# A31L22x register map
Vendor: VENDOR ABOV Semiconductor Co., Ltd.; Series: A31L22x; File version: 1.0
CPU: CM0+ r0p1, little endian, no MPU, no FPU, VTOR, 2 interrupt priority bits
Registers are 32-bit, read-write, reset 0x0 unless marked. A register's access mark holds for its fields unless they carry their own. Offsets are from the block's base; [hi:lo] are bit positions.

## TIMER5n — Timer/Counter 5n
Base 0x55000000
Same registers: TIMER50 0x40002B00
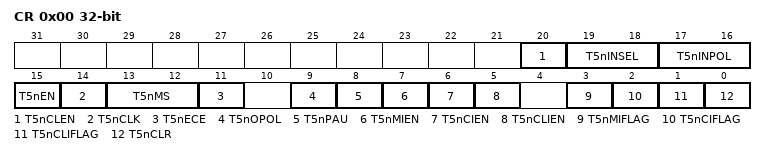
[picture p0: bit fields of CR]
0x00 CR — TIMER5n Control Register
  [20] T5nCLEN — TIMER5n Counter Clear Input Enable
    0=Disable counter clear input; 1=Enable counter clear input at a valid edge by TnINPOL[1:0] bits
  [19:18] T5nINSEL — TIMER5n Capture Signal Selection
    0=ExtClock (Select the external clock.); 1=XSOSC (Select XSOSC.); 2=WDTRC (Select WDTRC.)
  [17:16] T5nINPOL — TIMER5n Capture/'Counter Clear Input' Polarity Selection
    0=FallingEdge (Capture or 'Counter Clear Input' on Falling Edge); 1=RisingEdge (Capture or 'Counter Clear Input' on Rising Edge); 2=BothEdge (Capture or 'Counter Clear Input' on both of Falling and Rising Edge)
  [15] T5nEN — TIMER5n Operation Enable
    0=Disable the timer operation; 1=Enable the timer operation
  [14] T5nCLK — TIMER5n Clock Selection
    0=IntPrescaledClock (Select the internal prescaled clock.); 1=ExtClock (Select the external clock.)
  [13:12] T5nMS — TIMER5n Operation Mode Selection
    0=Interval mode. (T5nOUT: toggle at A-match); 1=Capture mode. (The A-match interrupt can occur); 2=OneShotMode (PPG one-shot mode. (T5nOUT: Programmable pulse output)); 3=PWMMode (PPG repeat mode. (T5nOUT: Programmable pulse output))
  [11] T5nECE — TIMER5n External Clock Edge Selection
    0=FallingEdge (Select falling edge of external clock.); 1=RisingEdge (Select rising edge of external clock.)
  [9] T5nOPOL — T5nOUT Polarity Selection
    0=Start high. (T5nOUT is low level at disable); 1=Start low. (T5nOUT is high level at disable)
  [8] T5nPAU — TIMER5n Counter Temporary Pause Control
    0=Disable (Continue counting); 1=Enable (Temporary pause)
  [7] T5nMIEN — TIMER5n Match Interrupt Enable
    0=Disable the match interrupt; 1=Enable the match interrupt
  [6] T5nCIEN — TIMER5n Capture Interrupt Enable
    0=Disable the capture interrupt; 1=Enable the capture interrupt
  [5] T5nCLIEN — TIMER5n Counter Clear Interrupt Enable
    0=Disable the counter clear input interrupt; 1=Enable the counter clear input interrupt
  [3] T5nMIFLAG — TIMER5n Match Interrupt Flag
    0=No request occurred; 1=Request occurred
  [2] T5nCIFLAG — TIMER5n Capture Interrupt Flag
    0=No request occurred; 1=Request occurred
  [1] T5nCLIFLAG — TIMER5n Counter Clear Input Interrupt Flag
    0=No request occurred; 1=Request occurred
  [0] T5nCLR — TIMER5n Counter and Prescaler Clear
    0=NoEffect; 1=Clear Counter and Prescaler. (Automatically cleared to '0' after operation)
0x04 ADR reset 0xFFFF — TIMER5n A Data Register
  [15:0] ADATA — TIMER5n A Data
0x08 BDR reset 0xFFFF — TIMER5n B Data Register
  [15:0] BDATA — TIMER5n B Data
0x0C CAPDR ro — TIMER5n Capture Data Register
  [15:0] CAPD — TIMER5n Capture Data
0x10 PREDR reset 0xFF — TIMER5n Prescaler Data Register
  [7:0] PRED — TIMER5n Prescaler Data
0x14 CNT ro — TIMER5n Counter Register
  [15:0] CNT — TIMER5n Counter

## TIMER6n — Timer/Counter 6n
Base 0x56000000
Same registers: TIMER60 0x40002F00
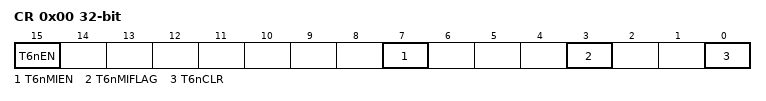
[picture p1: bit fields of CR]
0x00 CR — TIMER6n Control Register
  [15] T6nEN — TIMER6n Operation Enable
    0=Disable timer 60 operation and 100Hz RC oscillator; 1=Enable timer 60 operation and 100Hz RC oscillator
  [7] T6nMIEN — TIMER6n Match Interrupt Enable
    0=Disable the match interrupt; 1=Enable the match interrupt
  [3] T6nMIFLAG — TIMER6n Match Interrupt Flag
    0=No request occurred; 1=Request occurred. This bit is cleared to '0' when write '1'.
  [0] T6nCLR — TIMER6n Counter Clear
    0=NoEffect; 1=Clear Counter. (Automatically cleared to '0' after operation)
0x04 DR reset 0xFFFF — TIMER6n Data Register
  [15:0] DATA — TIMER6n Data
0x08 CNT ro — TIMER6n Counter Register
  [15:0] CNT — TIMER6n Counter
